# RasbperryPi register map
File version: 1
Registers are 32-bit, read-write, reset 0x0 unless marked. A register's access mark holds for its fields unless they carry their own. Offsets are from the block's base; [hi:lo] are bit positions; {n}, {i} and the like mark numbered series.

## RNG — Derived from rng.h apb_id: 0x20726E67
Base 0x7E104000
Same registers: RNG 0x7E104000, RNG 0x7E104000
0x00 CTRL reset not defined
  [31:0] data
0x04 STATUS reset not defined
  [31:0] data
0x08 DATA reset not defined
0x0C FF_THRESHOLD reset not defined
  [31:0] data
0x10 INT_MASK reset not defined
  [31:0] data

## APHY_CSR — Derived from sdc_addr_front.h
Base 0x7EE06000
0x00 ADDR_REV_ID reset not defined
  [31:0] data

## SD — Derived from sdc_ctrl.h apb_id: 0x5344434F
Base 0x7EE00000
0x00 CS 25-bit reset not defined
  [24] STALLING, [23] EXCEPTION, [22:19] ASHDN_T, [18] DEL_KEEP, [17] ASHDNE, [16] RDH_IDLE, [15] SDUP, [14] CLKOFF, [13:12] _, [11:10] DLLCAL, [9] IDLE, [8] SREF2RUN, [7] STOP, [6] STATEN, [5] SDTST, [4] PUSKIP, [3] STBY, [2] DPD, [1] EN, [0] RESTRT
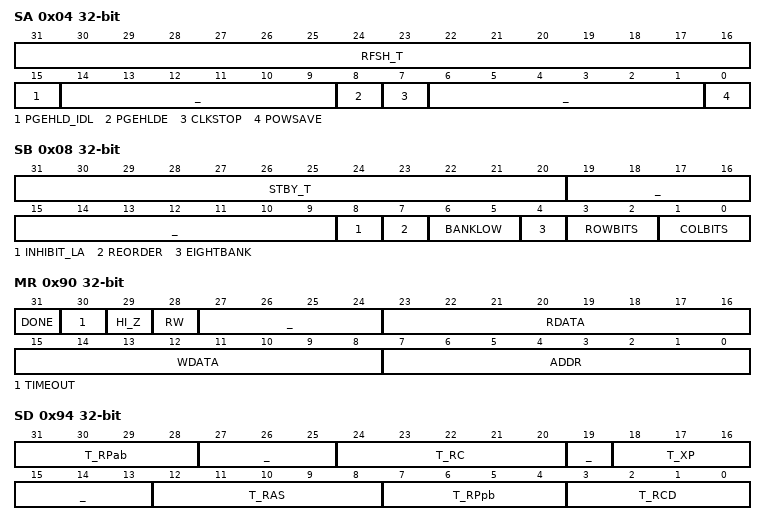
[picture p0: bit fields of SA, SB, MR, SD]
0x04 SA reset not defined
  [31:16] RFSH_T, [15] PGEHLD_IDL, [14:9] _, [8] PGEHLDE, [7] CLKSTOP, [6:1] _, [0] POWSAVE
0x08 SB reset not defined
  [31:20] STBY_T, [19:9] _, [8] INHIBIT_LA, [7] REORDER, [6:5] BANKLOW, [4] EIGHTBANK, [3:2] ROWBITS, [1:0] COLBITS
0x0C SC 31-bit reset not defined
  [30:24] T_RFC, [23:20] T_RRD, [19:12] _, [11:8] T_WR, [7] _, [6:4] T_WTR, [3] _, [2:0] WL
0x90 MR reset not defined
  [31] DONE, [30] TIMEOUT, [29] HI_Z, [28] RW, [27:24] _, [23:16] RDATA, [15:8] WDATA, [7:0] ADDR
0x94 SD reset not defined
  [31:28] T_RPab, [27:25] _, [24:20] T_RC, [19] _, [18:16] T_XP, [15:13] _, [12:8] T_RAS, [7:4] T_RPpb, [3:0] T_RCD
0x98 SE 29-bit reset not defined
  [28] RL_EN, [27:26] _, [25:20] RL, [19:18] _, [17:12] T_FAW, [11] _, [10:8] T_RTP, [7:6] _, [5:0] T_XSR
0xB4 SF 30-bit reset not defined
  [29] PHYHOLD, [28:19] PGEHLD_T, [18:9] POWSAV_T, [8:0] MDLL_CAL

## DPHY_CSR — Derived from sdc_dq_front.h
Base 0x7EE07000
0x00 DQ_REV_ID reset not defined
  [31:0] data

## SH — Derived from sdhost.h
Base 0x7E202000
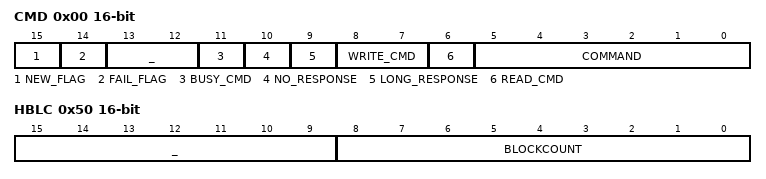
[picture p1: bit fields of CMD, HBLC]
0x00 CMD 16-bit
  [15] NEW_FLAG, [14] FAIL_FLAG, [13:12] _, [11] BUSY_CMD, [10] NO_RESPONSE, [9] LONG_RESPONSE, [8:7] WRITE_CMD, [6] READ_CMD, [5:0] COMMAND
0x04 ARG
  [31:0] ARGUMENT
0x08 TOUT
  [31:0] TIME_OUT
0x0C CDIV 11-bit reset 0xFB
  [10:0] CLOCKDIV
0x10 RSP0 ro reset not defined
  [31:0] CARD_STATUS
{0x10+4i} RSP{i} ro (i=1..3)
  [31:0] CID_CSD
0x20 HSTS 11-bit
  [10] BUSY_IRPT, [9] BLOCK_IRPT, [8] SDIO_IRPT, [7] REW_TIME_OUT, [6] CMD_TIME_OUT, [5] CRC16_ERROR, [4] CRC7_ERROR, [3] FIFO_ERROR, [2:1] _, [0] DATA_FLAG
0x30 VDD 1-bit
  [0] POWER_ON
0x34 EDM 19-bit reset not defined
  [18:14] READ_THRESHOLD, [13:9] WRITE_THRESHOLD, [8:4] FIFO_COUNT, [3:0] STATE_MACHINE
0x38 HCFG 11-bit
  [10] BUSY_IRPT_EN, [9] _, [8] BLOCK_IRPT_EN, [7:6] _, [5] SDIO_IRPT_EN, [4] DATA_IRPT_EN, [3] SLOW_CARD, [2] WIDE_EXT_BUS, [1] WIDE_INT_BUS, [0] REL_CMD_LINE
0x3C HBCT
  [31:0] BYTECOUNT
0x40 DATA reset not defined
0x50 HBLC 16-bit
  [15:9] _, [8:0] BLOCKCOUNT

## SLIM — Derived from slimbus.h apb_id: 0x736C696D
Base 0x7E210000
0x00 CON reset 0xC1
  [31:0] data
0x00 MC_IN_CON 12-bit
  [11:0] data
{0x0+0x20*i} DCC{i}_PA0 24-bit (i=0..7)
  [23:0] data
0x00 DCC8_PA0 24-bit
  [23:0] data
0x04 CON2
  [31:0] data
0x04 MC_IN_STAT 4-bit
  [3:0] data
{0x4+0x20*i} DCC{i}_PA1 24-bit (i=0..7)
  [23:0] data
0x04 DCC8_PA1 24-bit
  [23:0] data
0x08 STAT 26-bit
  [25:0] data
{0x8+0x20*i} DCC{i}_CON (i=0..7)
  [31:0] data
0x08 DCC8_CON
  [31:0] data
0x0C FS 14-bit
  [13:0] data
{0xC+0x20*i} DCC{i}_STAT (i=0..7)
  [31:0] data
0x0C DCC8_STAT
  [31:0] data
0x10 EA0
  [31:0] data
{0x10+0x20*i} DCC{i}_PROT reset 0xA0 (i=0..7)
  [31:0] data
0x10 DCC8_PROT reset 0xA0
  [31:0] data
0x14 EA1
  [31:0] data
0x20 DMA_MC_RX
  [31:0] data
0x20 MC_OUT_CON 7-bit
  [6:0] data
0x20 DCC9_PA0 24-bit
  [23:0] data
0x24 DMA_MC_TX
  [31:0] data
0x24 MC_OUT_STAT 4-bit
  [3:0] data
0x24 DCC9_PA1 24-bit
  [23:0] data
0x28 DCC9_CON
  [31:0] data
0x2C DCC9_STAT
  [31:0] data
{0x30+4i} DMA_DC{i} (i=0..9)
  [31:0] data
0x30 DCC9_PROT reset 0xA0
  [31:0] data
0x80 DMA_MC_CON 2-bit
  [1:0] data
0x84 DMA_DC_CON 20-bit
  [19:0] data
0x88 DMA_MC_STAT 4-bit
  [3:0] data
0x8C DMA_DC_STAT_0
  [31:0] data
0x90 DMA_DC_STAT_1 20-bit
  [19:0] data

## SLIM — Derived from slimbus_a0.h apb_id: 0x736C696D
Base 0x7E210000
0x00 CON reset 0xC1
  [31:0] data
0x00 SMC_IN_CON 12-bit
  [11:0] data
{0x0+0x20*i} DCC{i}_PA0 24-bit (i=0..7)
  [23:0] data
0x00 DCC8_PA0 24-bit
  [23:0] data
0x04 STAT 26-bit
  [25:0] data
0x04 SMC_IN_STAT 4-bit
  [3:0] data
{0x4+0x20*i} DCC{i}_PA1 24-bit (i=0..7)
  [23:0] data
0x04 DCC8_PA1 24-bit
  [23:0] data
0x08 FS 14-bit
  [13:0] data
0x08 CON2 1-bit
  [0] data
{0x8+0x20*i} DCC{i}_CON (i=0..7)
  [31:0] data
0x08 DCC8_CON
  [31:0] data
{0xC+0x20*i} DCC{i}_STAT (i=0..7)
  [31:0] data
0x0C DCC8_STAT
  [31:0] data
0x10 DMA_SMC_RX
  [31:0] data
0x14 DMA_SMC_TX
  [31:0] data
0x18 DMA_DC_RX
  [31:0] data
0x1C DMA_DC_TX
  [31:0] data
0x20 DMA_CON 4-bit
  [3:0] data
0x20 SMC_OUT_CON 8-bit
  [7:0] data
0x20 DCC9_PA0 24-bit
  [23:0] data
0x24 DMA_STAT 8-bit
  [7:0] data
0x24 SMC_OUT_STAT 4-bit
  [3:0] data
0x24 DCC9_PA1 24-bit
  [23:0] data
0x28 DCC9_CON
  [31:0] data
0x2C DCC9_STAT
  [31:0] data
0x30 EA0
  [31:0] data
0x34 EA1
  [31:0] data
